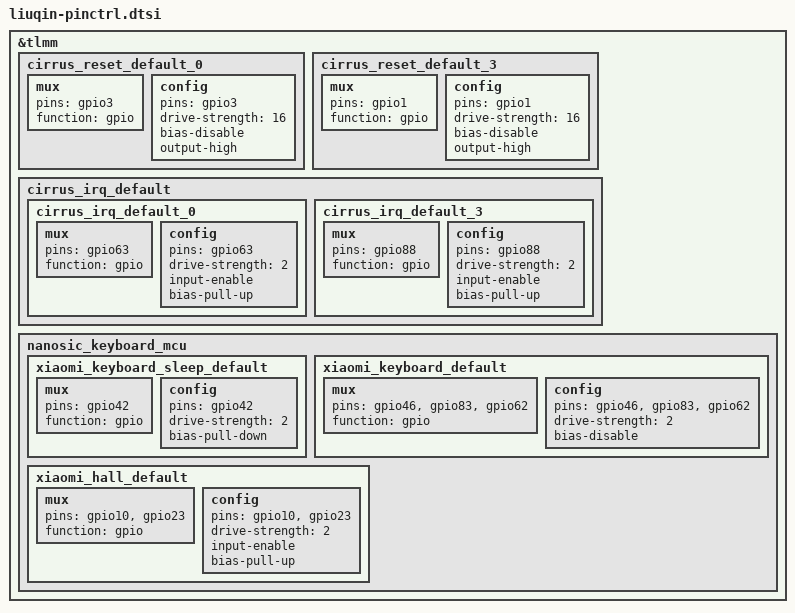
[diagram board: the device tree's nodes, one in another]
/*for unicorn pinctrl */

&tlmm {
	cirrus_reset_default_0: cirrus_reset_default_0 {
		mux {
			pins = "gpio3";
			function = "gpio";
		};

		config {
			pins = "gpio3";
			drive-strength = <16>;   /* 16 mA */
			bias-disable;
			output-high;
		};
	};

	cirrus_reset_default_3: cirrus_reset_default_3 {
		mux {
			pins = "gpio1";
			function = "gpio";
		};

		config {
			pins = "gpio1";
			drive-strength = <16>;   /* 16 mA */
			bias-disable;
			output-high;
		};
	};

	cirrus_irq_default {
		cirrus_irq_default_0: cirrus_irq_default_0 {
			mux {
				pins = "gpio63";
				function = "gpio";
			};
			config {
				pins = "gpio63";
				drive-strength = <2>;
				input-enable;
				bias-pull-up;
			};
		};
		cirrus_irq_default_3: cirrus_irq_default_3 {
			mux {
				pins = "gpio88";
				function = "gpio";
			};
			config {
				pins = "gpio88";
				drive-strength = <2>;
				input-enable;
				bias-pull-up;
			};
		};
	};


	nanosic_keyboard_mcu {
		xiaomi_keyboard_sleep_default: xiaomi_keyboard_sleep_default {
			mux {
				pins = "gpio42";
				function = "gpio";
			};
			config {
				pins = "gpio42";
				drive-strength = <2>;
				bias-pull-down;
			};
		};
		xiaomi_keyboard_default:xiaomi_keyboard_default {
			mux {
				pins = "gpio46", "gpio83","gpio62";
				function = "gpio";
			};
			config {
				pins = "gpio46", "gpio83","gpio62";
				drive-strength = <2>;
				bias-disable;
			};
		};
		xiaomi_hall_default: xiaomi_hall_default {
			mux {
				pins = "gpio10","gpio23";
				function = "gpio";
			};
			config {
				pins = "gpio10","gpio23";
				drive-strength = <2>;
				input-enable;
				bias-pull-up;
			};
		};
	};
};
